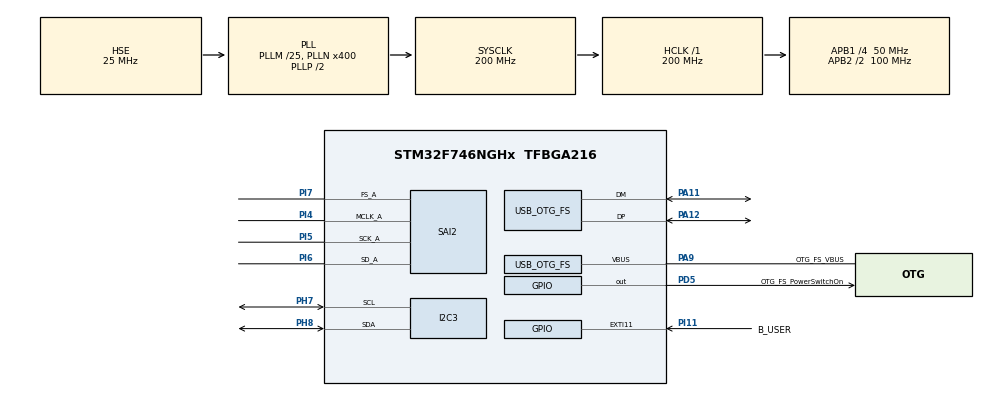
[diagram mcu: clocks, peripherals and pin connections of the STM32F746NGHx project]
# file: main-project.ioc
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CORTEX_M7.ART_ACCELERATOR_ENABLE=0
CORTEX_M7.AccessPermission-Cortex_Memory_Protection_Unit_Region1_Settings=MPU_REGION_FULL_ACCESS
CORTEX_M7.AccessPermission-Cortex_Memory_Protection_Unit_Region2_Settings=MPU_REGION_FULL_ACCESS
CORTEX_M7.BaseAddress-Cortex_Memory_Protection_Unit_Region1_Settings=0xC0000000
CORTEX_M7.BaseAddress-Cortex_Memory_Protection_Unit_Region2_Settings=0xA0000000
CORTEX_M7.CPU_DCache=Disabled
CORTEX_M7.CPU_ICache=Disabled
CORTEX_M7.DisableExec-Cortex_Memory_Protection_Unit_Region0_Settings=MPU_INSTRUCTION_ACCESS_DISABLE
CORTEX_M7.DisableExec-Cortex_Memory_Protection_Unit_Region2_Settings=MPU_INSTRUCTION_ACCESS_DISABLE
CORTEX_M7.Enable-Cortex_Memory_Protection_Unit_Region0_Settings=MPU_REGION_ENABLE
CORTEX_M7.Enable-Cortex_Memory_Protection_Unit_Region1_Settings=MPU_REGION_ENABLE
CORTEX_M7.Enable-Cortex_Memory_Protection_Unit_Region2_Settings=MPU_REGION_ENABLE
CORTEX_M7.FlashInterface=TCM_Enabled
CORTEX_M7.IsBufferable-Cortex_Memory_Protection_Unit_Region2_Settings=MPU_ACCESS_BUFFERABLE
CORTEX_M7.IsCacheable-Cortex_Memory_Protection_Unit_Region1_Settings=MPU_ACCESS_CACHEABLE
CORTEX_M7.IsShareable-Cortex_Memory_Protection_Unit_Region0_Settings=MPU_ACCESS_SHAREABLE
CORTEX_M7.IsShareable-Cortex_Memory_Protection_Unit_Region2_Settings=MPU_ACCESS_SHAREABLE
CORTEX_M7.MPU_Control=__NULL
CORTEX_M7.PREFETCH_ENABLE=0
CORTEX_M7.Size-Cortex_Memory_Protection_Unit_Region0_Settings=MPU_REGION_SIZE_4GB
CORTEX_M7.Size-Cortex_Memory_Protection_Unit_Region1_Settings=MPU_REGION_SIZE_32MB
CORTEX_M7.Size-Cortex_Memory_Protection_Unit_Region2_Settings=MPU_REGION_SIZE_8KB
CORTEX_M7.SubRegionDisable-Cortex_Memory_Protection_Unit_Region0_Settings=0x87
Dma.Request0=SAI2_A
Dma.SAI2_A.0.Direction=DMA_MEMORY_TO_PERIPH
Dma.SAI2_A.0.FIFOMode=DMA_FIFOMODE_ENABLE
Dma.SAI2_A.0.FIFOThreshold=DMA_FIFO_THRESHOLD_FULL
Dma.SAI2_A.0.Instance=DMA2_Stream4
Dma.SAI2_A.0.MemBurst=DMA_MBURST_SINGLE
Dma.SAI2_A.0.MemDataAlignment=DMA_MDATAALIGN_HALFWORD
Dma.SAI2_A.0.MemInc=DMA_MINC_ENABLE
Dma.SAI2_A.0.Mode=DMA_CIRCULAR
Dma.SAI2_A.0.PeriphBurst=DMA_PBURST_SINGLE
Dma.SAI2_A.0.PeriphDataAlignment=DMA_PDATAALIGN_HALFWORD
Dma.SAI2_A.0.PeriphInc=DMA_PINC_DISABLE
Dma.SAI2_A.0.Priority=DMA_PRIORITY_HIGH
FATFS._USE_LFN=1
I2C3.Timing=0x00C0EAFF
Mcu.Family=STM32F7
Mcu.Name=STM32F746NGHx
Mcu.Package=TFBGA216
NVIC.DMA2_Stream4_IRQn=true\:0\:0\:false\:false\:true\:false\:true\:true
NVIC.EXTI15_10_IRQn=true\:0\:0\:false\:false\:true\:true\:true\:true
NVIC.OTG_FS_IRQn=true\:6\:0\:true\:false\:true\:true\:true\:true
NVIC.PriorityGroup=NVIC_PRIORITYGROUP_4
PA11.GPIO_Speed=GPIO_SPEED_FREQ_HIGH
PA11.Mode=Host_Only
PA11.Signal=USB_OTG_FS_DM
PA12.GPIO_Speed=GPIO_SPEED_FREQ_HIGH
PA12.Mode=Host_Only
PA12.Signal=USB_OTG_FS_DP
PA9.GPIO_Label=OTG_FS_VBUS
PA9.Mode=Activate_VBUS
PA9.Signal=USB_OTG_FS_VBUS
PD5.GPIO_Label=OTG_FS_PowerSwitchOn
PD5.GPIO_PuPd=GPIO_PULLDOWN
PD5.Signal=GPIO_Output
PH0/OSC_IN.Mode=HSE-External-Oscillator
PH0/OSC_IN.Signal=RCC_OSC_IN
PH1/OSC_OUT.Mode=HSE-External-Oscillator
PH1/OSC_OUT.Signal=RCC_OSC_OUT
PH7.GPIO_Pu=GPIO_PULLUP
PH7.Mode=I2C
PH7.Signal=I2C3_SCL
PH8.GPIO_Pu=GPIO_PULLUP
PH8.Mode=I2C
PH8.Signal=I2C3_SDA
PI11.GPIO_Label=B_USER
PI11.GPIO_PuPd=GPIO_PULLDOWN
PI11.Signal=GPXTI11
PI4.GPIO_Speed=GPIO_SPEED_FREQ_HIGH
PI4.Mode=SAI_A_MasterWithClock
PI4.Signal=SAI2_MCLK_A
PI5.GPIO_Speed=GPIO_SPEED_FREQ_HIGH
PI5.Mode=SAI_A_MasterWithClock
PI5.Signal=SAI2_SCK_A
PI6.GPIO_Speed=GPIO_SPEED_FREQ_HIGH
PI6.Mode=SAI_A_MasterWithClock
PI6.Signal=SAI2_SD_A
PI7.GPIO_Speed=GPIO_SPEED_FREQ_HIGH
PI7.Mode=SAI_A_MasterWithClock
PI7.Signal=SAI2_FS_A
ProjectManager.HeapSize=0x200
ProjectManager.StackSize=0x400
ProjectManager.TargetToolchain=STM32CubeIDE
RCC.AHBFreq_Value=200000000
RCC.APB1CLKDivider=RCC_HCLK_DIV4
RCC.APB1Freq_Value=50000000
RCC.APB1TimFreq_Value=100000000
RCC.APB2CLKDivider=RCC_HCLK_DIV2
RCC.APB2Freq_Value=100000000
RCC.APB2TimFreq_Value=200000000
RCC.CortexFreq_Value=200000000
RCC.HCLKFreq_Value=200000000
RCC.HSE_VALUE=25000000
RCC.HSI_VALUE=16000000
RCC.LSE_VALUE=32768
RCC.PLL48CLockSelection=RCC_CLK48SOURCE_PLLSAIP
RCC.PLLI2SN=100
RCC.PLLM=25
RCC.PLLN=400
RCC.PLLQ=8
RCC.PLLSAIP=RCC_PLLSAIP_DIV4
RCC.PLLSAIQ=4
RCC.PLLSAIR=5
RCC.PLLSAIRDiv=RCC_PLLSAIDIVR_8
RCC.SDMMCClockSelection=RCC_SDMMC1CLKSOURCE_CLK48
RCC.SYSCLKFreq_VALUE=200000000
RCC.SYSCLKSource=RCC_SYSCLKSOURCE_PLLCLK
RCC.USBFreq_Value=48000000
RCC.VCOOutputFreq_Value=400000000
SAI2.ActiveFrameLength-SAI_A_MasterWithClock=32
SAI2.AudioFrequency-SAI_A_MasterWithClock=SAI_AUDIO_FREQUENCY_44K
SAI2.ClockStrobing-SAI_A_MasterWithClock=SAI_CLOCKSTROBING_RISINGEDGE
SAI2.DataSize-SAI_A_MasterWithClock=SAI_DATASIZE_16
SAI2.ErrorAudioFreq-SAI_A_MasterWithClock=6.53 %
SAI2.FIFOThreshold-SAI_A_MasterWithClock=SAI_FIFOTHRESHOLD_1QF
SAI2.FSDefinition-SAI_A_MasterWithClock=SAI_FS_CHANNEL_IDENTIFICATION
SAI2.FSOffset-SAI_A_MasterWithClock=SAI_FS_BEFOREFIRSTBIT
SAI2.FrameLength-SAI_A_MasterWithClock=64
SAI2.Instance-SAI_A_MasterWithClock=SAI$Index_Block_A
SAI2.MClockEnable-SAI_A_MasterWithClock=SAI_MASTERCLOCK_ENABLE
SAI2.OutputDrive-SAI_A_MasterWithClock=SAI_OUTPUTDRIVE_ENABLE
SAI2.RealAudioFreq-SAI_A_MasterWithClock=46.875 KHz
SAI2.SlotActive-SAI_A_MasterWithClock=0x0000FFFF
SAI2.SlotNumber-SAI_A_MasterWithClock=4
SAI2.VirtualMode-SAI_A_MasterWithClock=VM_MASTER
SAI2.VirtualSlotActive-SAI_A_MasterWithClock=SAI_SLOTACTIVE_ALL
USB_HOST.BSP.number=1
USB_HOST.USBH_HandleTypeDef-MSC_FS=hUsbHostFS
USB_HOST.VirtualModeFS=Msc
USB_HOST0.BSP.STBoard=false
USB_HOST0.BSP.api=Unknown
USB_HOST0.BSP.instance=PD5
USB_HOST0.BSP.ip=GPIO
USB_HOST0.BSP.mode=Output
USB_HOST0.BSP.name=Drive_VBUS_FS
USB_HOST0.BSP.solution=PD5
USB_OTG_FS.VirtualMode=Host_Only
USB_OTG_FS.phy_itface=HCD_PHY_EMBEDDED
VP_FATFS_VS_USB.Mode=USB
VP_USB_HOST_VS_USB_HOST_MSC_FS.Mode=MSC_FS
board=STM32F746G-DISCO

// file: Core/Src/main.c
/* USER CODE BEGIN Header */
/**
  ******************************************************************************
  * @file           : main.c
  * @brief          : Main program body
  ******************************************************************************
  * @attention
  *
  * Copyright (c) 2024 STMicroelectronics.
  * All rights reserved.
  *
  * This software is licensed under terms that can be found in the LICENSE file
  * in the root directory of this software component.
  * If no LICENSE file comes with this software, it is provided AS-IS.
  *
  ******************************************************************************
  */
/* USER CODE END Header */
#include "main.h"
#include "dma.h"
#include "fatfs.h"
#include "i2c.h"
#include "sai.h"
#include "usb_host.h"
#include "gpio.h"

/* USER CODE BEGIN Includes */
#include "waveplayer.h"
#include "stdbool.h"
/* USER CODE END Includes */

void SystemClock_Config(void);
void PeriphCommonClock_Config(void);
void MX_USB_HOST_Process(void);

/* USER CODE BEGIN PFP */
static void AUDIO_InitApplication(void);
/* USER CODE END PFP */

/* USER CODE BEGIN 0 */
extern ApplicationTypeDef Appli_state ;
extern AUDIO_PLAYBACK_StateTypeDef AudioState;
_Bool IsFinished = false;
/* USER CODE END 0 */

int main(void)
{

  /* MCU Configuration--------------------------------------------------------*/

  /* Reset of all peripherals, Initializes the Flash interface and the Systick. */
  HAL_Init();

  /* Configure the system clock */
  SystemClock_Config();

/* Configure the peripherals common clocks */
  PeriphCommonClock_Config();

  /* Initialize all configured peripherals */
  MX_GPIO_Init();
  MX_DMA_Init();
  MX_I2C3_Init();
  MX_SAI2_Init();
  MX_USB_HOST_Init();
  MX_FATFS_Init();

  /* Infinite loop */
  while (1)
  {
    MX_USB_HOST_Process();

    /* USER CODE BEGIN 3 */
    if(Appli_state == APPLICATION_READY)
    {
    	f_mount(&USBHFatFS,USBHPath,1);
    	AUDIO_PLAYER_Start(0);
    	while(false == IsFinished)
    	{
    		AUDIO_PLAYER_Process();
    		if(AudioState ==  AUDIO_STATE_STOP)
    		{
    			IsFinished = true;
    		}
    	}
    }
  }
  /* USER CODE END 3 */
}

void SystemClock_Config(void)
{
  RCC_OscInitTypeDef RCC_OscInitStruct = {0};
  RCC_ClkInitTypeDef RCC_ClkInitStruct = {0};

  /** Configure the main internal regulator output voltage
  */
  __HAL_RCC_PWR_CLK_ENABLE();
  __HAL_PWR_VOLTAGESCALING_CONFIG(PWR_REGULATOR_VOLTAGE_SCALE1);

  /** Initializes the RCC Oscillators according to the specified parameters
  * in the RCC_OscInitTypeDef structure.
  */
  RCC_OscInitStruct.OscillatorType = RCC_OSCILLATORTYPE_HSE;
  RCC_OscInitStruct.HSEState = RCC_HSE_ON;
  RCC_OscInitStruct.PLL.PLLState = RCC_PLL_ON;
  RCC_OscInitStruct.PLL.PLLSource = RCC_PLLSOURCE_HSE;
  RCC_OscInitStruct.PLL.PLLM = 25;
  RCC_OscInitStruct.PLL.PLLN = 400;
  RCC_OscInitStruct.PLL.PLLP = RCC_PLLP_DIV2;
  RCC_OscInitStruct.PLL.PLLQ = 8;
  if (HAL_RCC_OscConfig(&RCC_OscInitStruct) != HAL_OK)
  {
    Error_Handler();
  }

  /** Activate the Over-Drive mode
  */
  if (HAL_PWREx_EnableOverDrive() != HAL_OK)
  {
    Error_Handler();
  }

  /** Initializes the CPU, AHB and APB buses clocks
  */
  RCC_ClkInitStruct.ClockType = RCC_CLOCKTYPE_HCLK|RCC_CLOCKTYPE_SYSCLK
                              |RCC_CLOCKTYPE_PCLK1|RCC_CLOCKTYPE_PCLK2;
  RCC_ClkInitStruct.SYSCLKSource = RCC_SYSCLKSOURCE_PLLCLK;
  RCC_ClkInitStruct.AHBCLKDivider = RCC_SYSCLK_DIV1;
  RCC_ClkInitStruct.APB1CLKDivider = RCC_HCLK_DIV4;
  RCC_ClkInitStruct.APB2CLKDivider = RCC_HCLK_DIV2;

  if (HAL_RCC_ClockConfig(&RCC_ClkInitStruct, FLASH_LATENCY_6) != HAL_OK)
  {
    Error_Handler();
  }
}

void PeriphCommonClock_Config(void)
{
  RCC_PeriphCLKInitTypeDef PeriphClkInitStruct = {0};

  /** Initializes the peripherals clock
  */
  PeriphClkInitStruct.PeriphClockSelection = RCC_PERIPHCLK_SAI2|RCC_PERIPHCLK_CLK48;
  PeriphClkInitStruct.PLLSAI.PLLSAIN = 192;
  PeriphClkInitStruct.PLLSAI.PLLSAIR = 5;
  PeriphClkInitStruct.PLLSAI.PLLSAIQ = 4;
  PeriphClkInitStruct.PLLSAI.PLLSAIP = RCC_PLLSAIP_DIV4;
  PeriphClkInitStruct.PLLSAIDivQ = 1;
  PeriphClkInitStruct.PLLSAIDivR = RCC_PLLSAIDIVR_8;
  PeriphClkInitStruct.Sai2ClockSelection = RCC_SAI2CLKSOURCE_PLLSAI;
  PeriphClkInitStruct.Clk48ClockSelection = RCC_CLK48SOURCE_PLLSAIP;
  if (HAL_RCCEx_PeriphCLKConfig(&PeriphClkInitStruct) != HAL_OK)
  {
    Error_Handler();
  }
}

void Error_Handler(void)
{
  __disable_irq();
  while (1)
  {
  }
}
